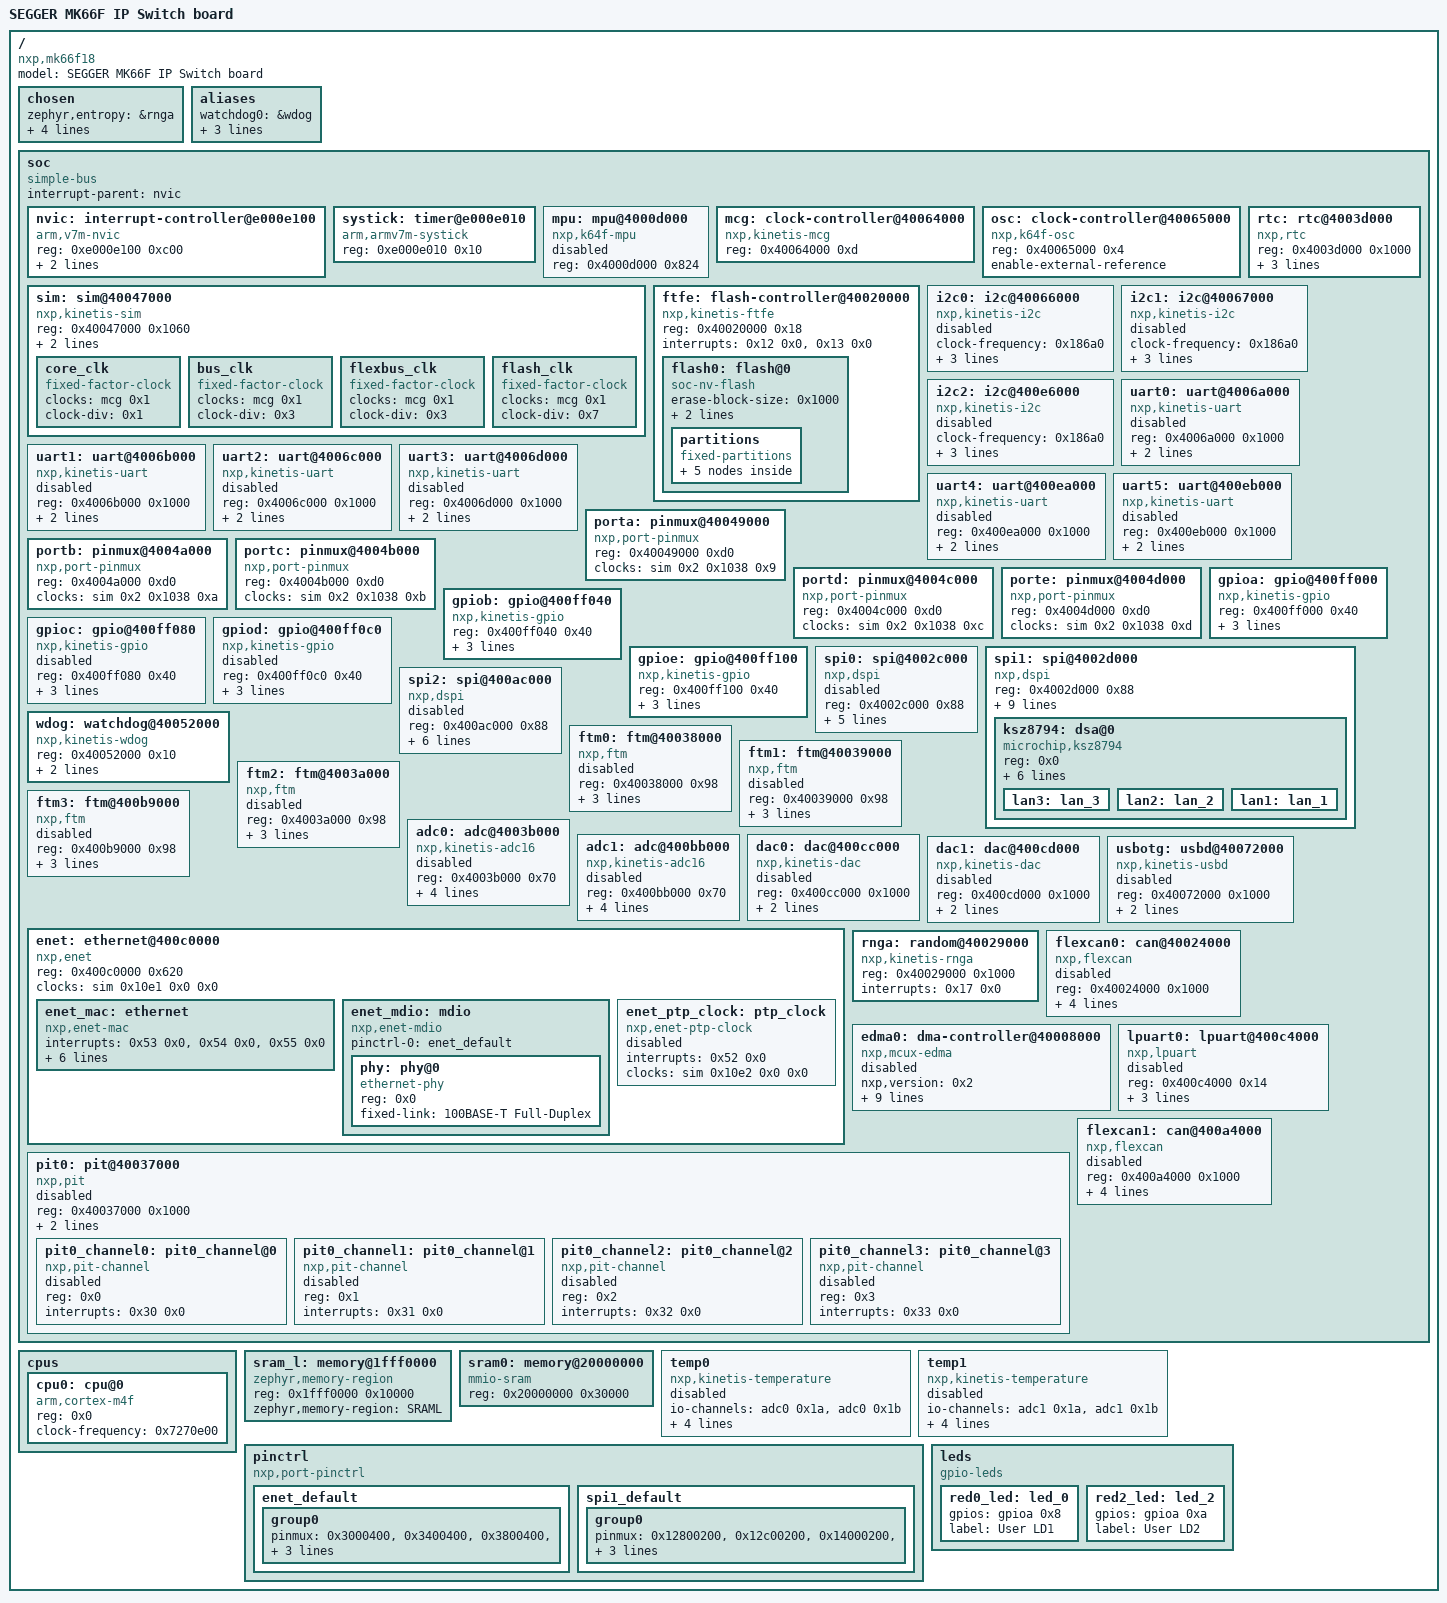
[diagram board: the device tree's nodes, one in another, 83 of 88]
/dts-v1/;

/* node '/' defined in zephyr/dts/common/skeleton.dtsi:9 */
/ {
	#address-cells = < 0x1 >;               /* in zephyr/dts/common/skeleton.dtsi:10 */
	#size-cells = < 0x1 >;                  /* in zephyr/dts/common/skeleton.dtsi:11 */
	model = "SEGGER MK66F IP Switch board"; /* in zephyr/boards/segger/ip_k66f/ip_k66f.dts:14 */
	compatible = "nxp,mk66f18",
	             "nxp,k66f",
	             "nxp,k6x";                 /* in zephyr/boards/segger/ip_k66f/ip_k66f.dts:15 */

	/* node '/chosen' defined in zephyr/dts/common/skeleton.dtsi:13 */
	chosen {
		zephyr,entropy = &rnga;                   /* in zephyr/dts/arm/nxp/nxp_k6x.dtsi:18 */
		zephyr,flash-controller = &ftfe;          /* in zephyr/dts/arm/nxp/nxp_k6x.dtsi:19 */
		zephyr,sram = &sram0;                     /* in zephyr/boards/segger/ip_k66f/ip_k66f.dts:24 */
		zephyr,flash = &flash0;                   /* in zephyr/boards/segger/ip_k66f/ip_k66f.dts:25 */
		zephyr,code-partition = &slot0_partition; /* in zephyr/boards/segger/ip_k66f/ip_k66f.dts:26 */
	};

	/* node '/aliases' defined in zephyr/dts/common/skeleton.dtsi:15 */
	aliases {
		watchdog0 = &wdog; /* in zephyr/dts/arm/nxp/nxp_k6x.dtsi:14 */
		led0 = &red0_led;  /* in zephyr/boards/segger/ip_k66f/ip_k66f.dts:18 */
		led2 = &red2_led;  /* in zephyr/boards/segger/ip_k66f/ip_k66f.dts:19 */
		dsa-spi = &spi1;   /* in zephyr/boards/segger/ip_k66f/ip_k66f.dts:20 */
	};

	/* node '/soc' defined in zephyr/dts/arm/armv7-m.dtsi:6 */
	soc {
		#address-cells = < 0x1 >;     /* in zephyr/dts/arm/armv7-m.dtsi:7 */
		#size-cells = < 0x1 >;        /* in zephyr/dts/arm/armv7-m.dtsi:8 */
		compatible = "simple-bus";    /* in zephyr/dts/arm/armv7-m.dtsi:9 */
		interrupt-parent = < &nvic >; /* in zephyr/dts/arm/armv7-m.dtsi:10 */
		ranges;                       /* in zephyr/dts/arm/armv7-m.dtsi:11 */

		/* node '/soc/interrupt-controller@e000e100' defined in zephyr/dts/arm/armv7-m.dtsi:13 */
		nvic: interrupt-controller@e000e100 {
			#address-cells = < 0x1 >;            /* in zephyr/dts/arm/armv7-m.dtsi:14 */
			compatible = "arm,v7m-nvic";         /* in zephyr/dts/arm/armv7-m.dtsi:15 */
			reg = < 0xe000e100 0xc00 >;          /* in zephyr/dts/arm/armv7-m.dtsi:16 */
			interrupt-controller;                /* in zephyr/dts/arm/armv7-m.dtsi:17 */
			#interrupt-cells = < 0x2 >;          /* in zephyr/dts/arm/armv7-m.dtsi:18 */
			arm,num-irq-priority-bits = < 0x4 >; /* in zephyr/dts/arm/nxp/nxp_k6x.dtsi:584 */
			phandle = < 0x1 >;                   /* in zephyr/dts/arm/armv7-m.dtsi:10 */
		};

		/* node '/soc/timer@e000e010' defined in zephyr/dts/arm/armv7-m.dtsi:21 */
		systick: timer@e000e010 {
			compatible = "arm,armv7m-systick"; /* in zephyr/dts/arm/armv7-m.dtsi:22 */
			reg = < 0xe000e010 0x10 >;         /* in zephyr/dts/arm/armv7-m.dtsi:23 */
		};

		/* node '/soc/mpu@4000d000' defined in zephyr/dts/arm/nxp/nxp_k6x.dtsi:82 */
		mpu: mpu@4000d000 {
			compatible = "nxp,k64f-mpu"; /* in zephyr/dts/arm/nxp/nxp_k6x.dtsi:83 */
			reg = < 0x4000d000 0x824 >;  /* in zephyr/dts/arm/nxp/nxp_k6x.dtsi:84 */
			status = "disabled";         /* in zephyr/dts/arm/nxp/nxp_k6x.dtsi:86 */
		};

		/* node '/soc/clock-controller@40064000' defined in zephyr/dts/arm/nxp/nxp_k6x.dtsi:89 */
		mcg: clock-controller@40064000 {
			compatible = "nxp,kinetis-mcg"; /* in zephyr/dts/arm/nxp/nxp_k6x.dtsi:90 */
			reg = < 0x40064000 0xd >;       /* in zephyr/dts/arm/nxp/nxp_k6x.dtsi:91 */
			#clock-cells = < 0x1 >;         /* in zephyr/dts/arm/nxp/nxp_k6x.dtsi:92 */
			phandle = < 0x2 >;              /* in zephyr/dts/arm/nxp/nxp_k6x.dtsi:118 */
		};

		/* node '/soc/clock-controller@40065000' defined in zephyr/dts/arm/nxp/nxp_k6x.dtsi:95 */
		osc: clock-controller@40065000 {
			compatible = "nxp,k64f-osc"; /* in zephyr/dts/arm/nxp/nxp_k6x.dtsi:96 */
			reg = < 0x40065000 0x4 >;    /* in zephyr/dts/arm/nxp/nxp_k6x.dtsi:97 */
			enable-external-reference;   /* in zephyr/dts/arm/nxp/nxp_k6x.dtsi:99 */
		};

		/* node '/soc/rtc@4003d000' defined in zephyr/dts/arm/nxp/nxp_k6x.dtsi:102 */
		rtc: rtc@4003d000 {
			compatible = "nxp,rtc";       /* in zephyr/dts/arm/nxp/nxp_k6x.dtsi:103 */
			reg = < 0x4003d000 0x1000 >;  /* in zephyr/dts/arm/nxp/nxp_k6x.dtsi:104 */
			interrupts = < 0x2e 0x0 >,
			             < 0x2f 0x0 >;    /* in zephyr/dts/arm/nxp/nxp_k6x.dtsi:105 */
			interrupt-names = "alarm",
			                  "seconds";  /* in zephyr/dts/arm/nxp/nxp_k6x.dtsi:106 */
			clock-frequency = < 0x8000 >; /* in zephyr/dts/arm/nxp/nxp_k6x.dtsi:107 */
			prescaler = < 0x8000 >;       /* in zephyr/dts/arm/nxp/nxp_k6x.dtsi:108 */
		};

		/* node '/soc/sim@40047000' defined in zephyr/dts/arm/nxp/nxp_k6x.dtsi:111 */
		sim: sim@40047000 {
			compatible = "nxp,kinetis-sim"; /* in zephyr/dts/arm/nxp/nxp_k6x.dtsi:112 */
			reg = < 0x40047000 0x1060 >;    /* in zephyr/dts/arm/nxp/nxp_k6x.dtsi:113 */
			#clock-cells = < 0x3 >;         /* in zephyr/dts/arm/nxp/nxp_k6x.dtsi:114 */
			pllfll-select = < 0x1 >;        /* in zephyr/boards/segger/ip_k66f/ip_k66f.dts:49 */
			er32k-select = < 0x2 >;         /* in zephyr/boards/segger/ip_k66f/ip_k66f.dts:50 */
			phandle = < 0x3 >;              /* in zephyr/dts/arm/nxp/nxp_k6x.dtsi:170 */

			/* node '/soc/sim@40047000/core_clk' defined in zephyr/dts/arm/nxp/nxp_k6x.dtsi:116 */
			core_clk {
				compatible = "fixed-factor-clock"; /* in zephyr/dts/arm/nxp/nxp_k6x.dtsi:117 */
				clocks = < &mcg 0x1 >;             /* in zephyr/dts/arm/nxp/nxp_k6x.dtsi:118 */
				clock-div = < 0x1 >;               /* in zephyr/dts/arm/nxp/nxp_k6x.dtsi:119 */
				#clock-cells = < 0x0 >;            /* in zephyr/dts/arm/nxp/nxp_k6x.dtsi:120 */
			};

			/* node '/soc/sim@40047000/bus_clk' defined in zephyr/dts/arm/nxp/nxp_k6x.dtsi:123 */
			bus_clk {
				compatible = "fixed-factor-clock"; /* in zephyr/dts/arm/nxp/nxp_k6x.dtsi:124 */
				clocks = < &mcg 0x1 >;             /* in zephyr/dts/arm/nxp/nxp_k6x.dtsi:125 */
				#clock-cells = < 0x0 >;            /* in zephyr/dts/arm/nxp/nxp_k6x.dtsi:127 */
				clock-div = < 0x3 >;               /* in zephyr/boards/segger/ip_k66f/ip_k66f.dts:53 */
			};

			/* node '/soc/sim@40047000/flexbus_clk' defined in zephyr/dts/arm/nxp/nxp_k6x.dtsi:130 */
			flexbus_clk {
				compatible = "fixed-factor-clock"; /* in zephyr/dts/arm/nxp/nxp_k6x.dtsi:131 */
				clocks = < &mcg 0x1 >;             /* in zephyr/dts/arm/nxp/nxp_k6x.dtsi:132 */
				clock-div = < 0x3 >;               /* in zephyr/dts/arm/nxp/nxp_k6x.dtsi:133 */
				#clock-cells = < 0x0 >;            /* in zephyr/dts/arm/nxp/nxp_k6x.dtsi:134 */
			};

			/* node '/soc/sim@40047000/flash_clk' defined in zephyr/dts/arm/nxp/nxp_k6x.dtsi:137 */
			flash_clk {
				compatible = "fixed-factor-clock"; /* in zephyr/dts/arm/nxp/nxp_k6x.dtsi:138 */
				clocks = < &mcg 0x1 >;             /* in zephyr/dts/arm/nxp/nxp_k6x.dtsi:139 */
				#clock-cells = < 0x0 >;            /* in zephyr/dts/arm/nxp/nxp_k6x.dtsi:141 */
				clock-div = < 0x7 >;               /* in zephyr/boards/segger/ip_k66f/ip_k66f.dts:57 */
			};
		};

		/* node '/soc/flash-controller@40020000' defined in zephyr/dts/arm/nxp/nxp_k6x.dtsi:145 */
		ftfe: flash-controller@40020000 {
			compatible = "nxp,kinetis-ftfe";      /* in zephyr/dts/arm/nxp/nxp_k6x.dtsi:146 */
			reg = < 0x40020000 0x18 >;            /* in zephyr/dts/arm/nxp/nxp_k6x.dtsi:147 */
			interrupts = < 0x12 0x0 >,
			             < 0x13 0x0 >;            /* in zephyr/dts/arm/nxp/nxp_k6x.dtsi:148 */
			interrupt-names = "command-complete",
			                  "read-collision";   /* in zephyr/dts/arm/nxp/nxp_k6x.dtsi:149 */
			status = "okay";                      /* in zephyr/dts/arm/nxp/nxp_k6x.dtsi:150 */
			#address-cells = < 0x1 >;             /* in zephyr/dts/arm/nxp/nxp_k6x.dtsi:152 */
			#size-cells = < 0x1 >;                /* in zephyr/dts/arm/nxp/nxp_k6x.dtsi:153 */

			/* node '/soc/flash-controller@40020000/flash@0' defined in zephyr/dts/arm/nxp/nxp_k6x.dtsi:155 */
			flash0: flash@0 {
				compatible = "soc-nv-flash";   /* in zephyr/dts/arm/nxp/nxp_k6x.dtsi:156 */
				erase-block-size = < 0x1000 >; /* in zephyr/dts/arm/nxp/nxp_k6x.dtsi:158 */
				write-block-size = < 0x8 >;    /* in zephyr/dts/arm/nxp/nxp_k6x.dtsi:159 */
				reg = < 0x0 0x200000 >;        /* in zephyr/dts/arm/nxp/nxp_k66.dtsi:12 */

				/* node '/soc/flash-controller@40020000/flash@0/partitions' defined in zephyr/boards/segger/ip_k66f/ip_k66f.dts:70 */
				partitions {
					compatible = "fixed-partitions"; /* in zephyr/boards/segger/ip_k66f/ip_k66f.dts:71 */
					#address-cells = < 0x1 >;        /* in zephyr/boards/segger/ip_k66f/ip_k66f.dts:72 */
					#size-cells = < 0x1 >;           /* in zephyr/boards/segger/ip_k66f/ip_k66f.dts:73 */

					/* node '/soc/flash-controller@40020000/flash@0/partitions/partition@0' defined in zephyr/boards/segger/ip_k66f/ip_k66f.dts:75 */
					boot_partition: partition@0 {
						label = "mcuboot";     /* in zephyr/boards/segger/ip_k66f/ip_k66f.dts:76 */
						reg = < 0x0 0x10000 >; /* in zephyr/boards/segger/ip_k66f/ip_k66f.dts:77 */
						read-only;             /* in zephyr/boards/segger/ip_k66f/ip_k66f.dts:78 */
					};

					/* node '/soc/flash-controller@40020000/flash@0/partitions/partition@1e000' defined in zephyr/boards/segger/ip_k66f/ip_k66f.dts:86 */
					storage_partition: partition@1e000 {
						label = "storage";        /* in zephyr/boards/segger/ip_k66f/ip_k66f.dts:87 */
						reg = < 0x1e000 0x2000 >; /* in zephyr/boards/segger/ip_k66f/ip_k66f.dts:88 */
					};

					/* node '/soc/flash-controller@40020000/flash@0/partitions/partition@20000' defined in zephyr/boards/segger/ip_k66f/ip_k66f.dts:91 */
					slot0_partition: partition@20000 {
						label = "image-0";         /* in zephyr/boards/segger/ip_k66f/ip_k66f.dts:92 */
						reg = < 0x20000 0x60000 >; /* in zephyr/boards/segger/ip_k66f/ip_k66f.dts:93 */
					};

					/* node '/soc/flash-controller@40020000/flash@0/partitions/partition@80000' defined in zephyr/boards/segger/ip_k66f/ip_k66f.dts:96 */
					slot1_partition: partition@80000 {
						label = "image-1";         /* in zephyr/boards/segger/ip_k66f/ip_k66f.dts:97 */
						reg = < 0x80000 0x60000 >; /* in zephyr/boards/segger/ip_k66f/ip_k66f.dts:98 */
					};

					/* node '/soc/flash-controller@40020000/flash@0/partitions/partition@e0000' defined in zephyr/boards/segger/ip_k66f/ip_k66f.dts:101 */
					scratch_partition: partition@e0000 {
						label = "image-scratch";   /* in zephyr/boards/segger/ip_k66f/ip_k66f.dts:102 */
						reg = < 0xe0000 0x20000 >; /* in zephyr/boards/segger/ip_k66f/ip_k66f.dts:103 */
					};
				};
			};
		};

		/* node '/soc/i2c@40066000' defined in zephyr/dts/arm/nxp/nxp_k6x.dtsi:163 */
		i2c0: i2c@40066000 {
			compatible = "nxp,kinetis-i2c";   /* in zephyr/dts/arm/nxp/nxp_k6x.dtsi:164 */
			clock-frequency = < 0x186a0 >;    /* in zephyr/dts/arm/nxp/nxp_k6x.dtsi:165 */
			#address-cells = < 0x1 >;         /* in zephyr/dts/arm/nxp/nxp_k6x.dtsi:166 */
			#size-cells = < 0x0 >;            /* in zephyr/dts/arm/nxp/nxp_k6x.dtsi:167 */
			reg = < 0x40066000 0x1000 >;      /* in zephyr/dts/arm/nxp/nxp_k6x.dtsi:168 */
			interrupts = < 0x18 0x0 >;        /* in zephyr/dts/arm/nxp/nxp_k6x.dtsi:169 */
			clocks = < &sim 0x2 0x1034 0x6 >; /* in zephyr/dts/arm/nxp/nxp_k6x.dtsi:170 */
			status = "disabled";              /* in zephyr/dts/arm/nxp/nxp_k6x.dtsi:171 */
		};

		/* node '/soc/i2c@40067000' defined in zephyr/dts/arm/nxp/nxp_k6x.dtsi:174 */
		i2c1: i2c@40067000 {
			compatible = "nxp,kinetis-i2c";   /* in zephyr/dts/arm/nxp/nxp_k6x.dtsi:175 */
			clock-frequency = < 0x186a0 >;    /* in zephyr/dts/arm/nxp/nxp_k6x.dtsi:176 */
			#address-cells = < 0x1 >;         /* in zephyr/dts/arm/nxp/nxp_k6x.dtsi:177 */
			#size-cells = < 0x0 >;            /* in zephyr/dts/arm/nxp/nxp_k6x.dtsi:178 */
			reg = < 0x40067000 0x1000 >;      /* in zephyr/dts/arm/nxp/nxp_k6x.dtsi:179 */
			interrupts = < 0x19 0x0 >;        /* in zephyr/dts/arm/nxp/nxp_k6x.dtsi:180 */
			clocks = < &sim 0x2 0x1034 0x7 >; /* in zephyr/dts/arm/nxp/nxp_k6x.dtsi:181 */
			status = "disabled";              /* in zephyr/dts/arm/nxp/nxp_k6x.dtsi:182 */
		};

		/* node '/soc/i2c@400e6000' defined in zephyr/dts/arm/nxp/nxp_k6x.dtsi:185 */
		i2c2: i2c@400e6000 {
			compatible = "nxp,kinetis-i2c";   /* in zephyr/dts/arm/nxp/nxp_k6x.dtsi:186 */
			clock-frequency = < 0x186a0 >;    /* in zephyr/dts/arm/nxp/nxp_k6x.dtsi:187 */
			#address-cells = < 0x1 >;         /* in zephyr/dts/arm/nxp/nxp_k6x.dtsi:188 */
			#size-cells = < 0x0 >;            /* in zephyr/dts/arm/nxp/nxp_k6x.dtsi:189 */
			reg = < 0x400e6000 0x1000 >;      /* in zephyr/dts/arm/nxp/nxp_k6x.dtsi:190 */
			interrupts = < 0x4a 0x0 >;        /* in zephyr/dts/arm/nxp/nxp_k6x.dtsi:191 */
			clocks = < &sim 0x2 0x1028 0x6 >; /* in zephyr/dts/arm/nxp/nxp_k6x.dtsi:192 */
			status = "disabled";              /* in zephyr/dts/arm/nxp/nxp_k6x.dtsi:193 */
		};

		/* node '/soc/uart@4006a000' defined in zephyr/dts/arm/nxp/nxp_k6x.dtsi:196 */
		uart0: uart@4006a000 {
			compatible = "nxp,kinetis-uart";  /* in zephyr/dts/arm/nxp/nxp_k6x.dtsi:197 */
			reg = < 0x4006a000 0x1000 >;      /* in zephyr/dts/arm/nxp/nxp_k6x.dtsi:198 */
			interrupts = < 0x1f 0x0 >,
			             < 0x20 0x0 >;        /* in zephyr/dts/arm/nxp/nxp_k6x.dtsi:199 */
			interrupt-names = "status",
			                  "error";        /* in zephyr/dts/arm/nxp/nxp_k6x.dtsi:200 */
			clocks = < &sim 0x0 0x1034 0xa >; /* in zephyr/dts/arm/nxp/nxp_k6x.dtsi:201 */
			status = "disabled";              /* in zephyr/dts/arm/nxp/nxp_k6x.dtsi:203 */
		};

		/* node '/soc/uart@4006b000' defined in zephyr/dts/arm/nxp/nxp_k6x.dtsi:206 */
		uart1: uart@4006b000 {
			compatible = "nxp,kinetis-uart";  /* in zephyr/dts/arm/nxp/nxp_k6x.dtsi:207 */
			reg = < 0x4006b000 0x1000 >;      /* in zephyr/dts/arm/nxp/nxp_k6x.dtsi:208 */
			interrupts = < 0x21 0x0 >,
			             < 0x22 0x0 >;        /* in zephyr/dts/arm/nxp/nxp_k6x.dtsi:209 */
			interrupt-names = "status",
			                  "error";        /* in zephyr/dts/arm/nxp/nxp_k6x.dtsi:210 */
			clocks = < &sim 0x0 0x1034 0xb >; /* in zephyr/dts/arm/nxp/nxp_k6x.dtsi:211 */
			status = "disabled";              /* in zephyr/dts/arm/nxp/nxp_k6x.dtsi:213 */
		};

		/* node '/soc/uart@4006c000' defined in zephyr/dts/arm/nxp/nxp_k6x.dtsi:216 */
		uart2: uart@4006c000 {
			compatible = "nxp,kinetis-uart";  /* in zephyr/dts/arm/nxp/nxp_k6x.dtsi:217 */
			reg = < 0x4006c000 0x1000 >;      /* in zephyr/dts/arm/nxp/nxp_k6x.dtsi:218 */
			interrupts = < 0x23 0x0 >,
			             < 0x24 0x0 >;        /* in zephyr/dts/arm/nxp/nxp_k6x.dtsi:219 */
			interrupt-names = "status",
			                  "error";        /* in zephyr/dts/arm/nxp/nxp_k6x.dtsi:220 */
			clocks = < &sim 0x2 0x1034 0xc >; /* in zephyr/dts/arm/nxp/nxp_k6x.dtsi:221 */
			status = "disabled";              /* in zephyr/dts/arm/nxp/nxp_k6x.dtsi:223 */
		};

		/* node '/soc/uart@4006d000' defined in zephyr/dts/arm/nxp/nxp_k6x.dtsi:226 */
		uart3: uart@4006d000 {
			compatible = "nxp,kinetis-uart";  /* in zephyr/dts/arm/nxp/nxp_k6x.dtsi:227 */
			reg = < 0x4006d000 0x1000 >;      /* in zephyr/dts/arm/nxp/nxp_k6x.dtsi:228 */
			interrupts = < 0x25 0x0 >,
			             < 0x26 0x0 >;        /* in zephyr/dts/arm/nxp/nxp_k6x.dtsi:229 */
			interrupt-names = "status",
			                  "error";        /* in zephyr/dts/arm/nxp/nxp_k6x.dtsi:230 */
			clocks = < &sim 0x2 0x1034 0xd >; /* in zephyr/dts/arm/nxp/nxp_k6x.dtsi:231 */
			status = "disabled";              /* in zephyr/dts/arm/nxp/nxp_k6x.dtsi:233 */
		};

		/* node '/soc/uart@400ea000' defined in zephyr/dts/arm/nxp/nxp_k6x.dtsi:236 */
		uart4: uart@400ea000 {
			compatible = "nxp,kinetis-uart";  /* in zephyr/dts/arm/nxp/nxp_k6x.dtsi:237 */
			reg = < 0x400ea000 0x1000 >;      /* in zephyr/dts/arm/nxp/nxp_k6x.dtsi:238 */
			interrupts = < 0x42 0x0 >,
			             < 0x43 0x0 >;        /* in zephyr/dts/arm/nxp/nxp_k6x.dtsi:239 */
			interrupt-names = "status",
			                  "error";        /* in zephyr/dts/arm/nxp/nxp_k6x.dtsi:240 */
			clocks = < &sim 0x2 0x1028 0xa >; /* in zephyr/dts/arm/nxp/nxp_k6x.dtsi:241 */
			status = "disabled";              /* in zephyr/dts/arm/nxp/nxp_k6x.dtsi:243 */
		};

		/* node '/soc/uart@400eb000' defined in zephyr/dts/arm/nxp/nxp_k6x.dtsi:246 */
		uart5: uart@400eb000 {
			compatible = "nxp,kinetis-uart";  /* in zephyr/dts/arm/nxp/nxp_k6x.dtsi:247 */
			reg = < 0x400eb000 0x1000 >;      /* in zephyr/dts/arm/nxp/nxp_k6x.dtsi:248 */
			interrupts = < 0x44 0x0 >,
			             < 0x45 0x0 >;        /* in zephyr/dts/arm/nxp/nxp_k6x.dtsi:249 */
			interrupt-names = "status",
			                  "error";        /* in zephyr/dts/arm/nxp/nxp_k6x.dtsi:250 */
			clocks = < &sim 0x2 0x1028 0xb >; /* in zephyr/dts/arm/nxp/nxp_k6x.dtsi:251 */
			status = "disabled";              /* in zephyr/dts/arm/nxp/nxp_k6x.dtsi:253 */
		};

		/* node '/soc/pinmux@40049000' defined in zephyr/dts/arm/nxp/nxp_k6x.dtsi:256 */
		porta: pinmux@40049000 {
			compatible = "nxp,port-pinmux";   /* in zephyr/dts/arm/nxp/nxp_k6x.dtsi:257 */
			reg = < 0x40049000 0xd0 >;        /* in zephyr/dts/arm/nxp/nxp_k6x.dtsi:258 */
			clocks = < &sim 0x2 0x1038 0x9 >; /* in zephyr/dts/arm/nxp/nxp_k6x.dtsi:259 */
			phandle = < 0x4 >;                /* in zephyr/dts/arm/nxp/nxp_k6x.dtsi:293 */
		};

		/* node '/soc/pinmux@4004a000' defined in zephyr/dts/arm/nxp/nxp_k6x.dtsi:262 */
		portb: pinmux@4004a000 {
			compatible = "nxp,port-pinmux";   /* in zephyr/dts/arm/nxp/nxp_k6x.dtsi:263 */
			reg = < 0x4004a000 0xd0 >;        /* in zephyr/dts/arm/nxp/nxp_k6x.dtsi:264 */
			clocks = < &sim 0x2 0x1038 0xa >; /* in zephyr/dts/arm/nxp/nxp_k6x.dtsi:265 */
			phandle = < 0x5 >;                /* in zephyr/dts/arm/nxp/nxp_k6x.dtsi:303 */
		};

		/* node '/soc/pinmux@4004b000' defined in zephyr/dts/arm/nxp/nxp_k6x.dtsi:268 */
		portc: pinmux@4004b000 {
			compatible = "nxp,port-pinmux";   /* in zephyr/dts/arm/nxp/nxp_k6x.dtsi:269 */
			reg = < 0x4004b000 0xd0 >;        /* in zephyr/dts/arm/nxp/nxp_k6x.dtsi:270 */
			clocks = < &sim 0x2 0x1038 0xb >; /* in zephyr/dts/arm/nxp/nxp_k6x.dtsi:271 */
			phandle = < 0x6 >;                /* in zephyr/dts/arm/nxp/nxp_k6x.dtsi:313 */
		};

		/* node '/soc/pinmux@4004c000' defined in zephyr/dts/arm/nxp/nxp_k6x.dtsi:274 */
		portd: pinmux@4004c000 {
			compatible = "nxp,port-pinmux";   /* in zephyr/dts/arm/nxp/nxp_k6x.dtsi:275 */
			reg = < 0x4004c000 0xd0 >;        /* in zephyr/dts/arm/nxp/nxp_k6x.dtsi:276 */
			clocks = < &sim 0x2 0x1038 0xc >; /* in zephyr/dts/arm/nxp/nxp_k6x.dtsi:277 */
			phandle = < 0x7 >;                /* in zephyr/dts/arm/nxp/nxp_k6x.dtsi:323 */
		};

		/* node '/soc/pinmux@4004d000' defined in zephyr/dts/arm/nxp/nxp_k6x.dtsi:280 */
		porte: pinmux@4004d000 {
			compatible = "nxp,port-pinmux";   /* in zephyr/dts/arm/nxp/nxp_k6x.dtsi:281 */
			reg = < 0x4004d000 0xd0 >;        /* in zephyr/dts/arm/nxp/nxp_k6x.dtsi:282 */
			clocks = < &sim 0x2 0x1038 0xd >; /* in zephyr/dts/arm/nxp/nxp_k6x.dtsi:283 */
			phandle = < 0x8 >;                /* in zephyr/dts/arm/nxp/nxp_k6x.dtsi:333 */
		};

		/* node '/soc/gpio@400ff000' defined in zephyr/dts/arm/nxp/nxp_k6x.dtsi:286 */
		gpioa: gpio@400ff000 {
			compatible = "nxp,kinetis-gpio"; /* in zephyr/dts/arm/nxp/nxp_k6x.dtsi:287 */
			reg = < 0x400ff000 0x40 >;       /* in zephyr/dts/arm/nxp/nxp_k6x.dtsi:289 */
			interrupts = < 0x3b 0x2 >;       /* in zephyr/dts/arm/nxp/nxp_k6x.dtsi:290 */
			gpio-controller;                 /* in zephyr/dts/arm/nxp/nxp_k6x.dtsi:291 */
			#gpio-cells = < 0x2 >;           /* in zephyr/dts/arm/nxp/nxp_k6x.dtsi:292 */
			nxp,kinetis-port = < &porta >;   /* in zephyr/dts/arm/nxp/nxp_k6x.dtsi:293 */
			status = "okay";                 /* in zephyr/boards/segger/ip_k66f/ip_k66f.dts:159 */
			phandle = < 0x14 >;              /* in zephyr/boards/segger/ip_k66f/ip_k66f.dts:33 */
		};

		/* node '/soc/gpio@400ff040' defined in zephyr/dts/arm/nxp/nxp_k6x.dtsi:296 */
		gpiob: gpio@400ff040 {
			compatible = "nxp,kinetis-gpio"; /* in zephyr/dts/arm/nxp/nxp_k6x.dtsi:297 */
			reg = < 0x400ff040 0x40 >;       /* in zephyr/dts/arm/nxp/nxp_k6x.dtsi:299 */
			interrupts = < 0x3c 0x2 >;       /* in zephyr/dts/arm/nxp/nxp_k6x.dtsi:300 */
			gpio-controller;                 /* in zephyr/dts/arm/nxp/nxp_k6x.dtsi:301 */
			#gpio-cells = < 0x2 >;           /* in zephyr/dts/arm/nxp/nxp_k6x.dtsi:302 */
			nxp,kinetis-port = < &portb >;   /* in zephyr/dts/arm/nxp/nxp_k6x.dtsi:303 */
			status = "okay";                 /* in zephyr/boards/segger/ip_k66f/ip_k66f.dts:163 */
			phandle = < 0xc >;               /* in zephyr/boards/segger/ip_k66f/ip_k66f.dts:143 */
		};

		/* node '/soc/gpio@400ff080' defined in zephyr/dts/arm/nxp/nxp_k6x.dtsi:306 */
		gpioc: gpio@400ff080 {
			compatible = "nxp,kinetis-gpio"; /* in zephyr/dts/arm/nxp/nxp_k6x.dtsi:307 */
			status = "disabled";             /* in zephyr/dts/arm/nxp/nxp_k6x.dtsi:308 */
			reg = < 0x400ff080 0x40 >;       /* in zephyr/dts/arm/nxp/nxp_k6x.dtsi:309 */
			interrupts = < 0x3d 0x2 >;       /* in zephyr/dts/arm/nxp/nxp_k6x.dtsi:310 */
			gpio-controller;                 /* in zephyr/dts/arm/nxp/nxp_k6x.dtsi:311 */
			#gpio-cells = < 0x2 >;           /* in zephyr/dts/arm/nxp/nxp_k6x.dtsi:312 */
			nxp,kinetis-port = < &portc >;   /* in zephyr/dts/arm/nxp/nxp_k6x.dtsi:313 */
		};

		/* node '/soc/gpio@400ff0c0' defined in zephyr/dts/arm/nxp/nxp_k6x.dtsi:316 */
		gpiod: gpio@400ff0c0 {
			compatible = "nxp,kinetis-gpio"; /* in zephyr/dts/arm/nxp/nxp_k6x.dtsi:317 */
			status = "disabled";             /* in zephyr/dts/arm/nxp/nxp_k6x.dtsi:318 */
			reg = < 0x400ff0c0 0x40 >;       /* in zephyr/dts/arm/nxp/nxp_k6x.dtsi:319 */
			interrupts = < 0x3e 0x2 >;       /* in zephyr/dts/arm/nxp/nxp_k6x.dtsi:320 */
			gpio-controller;                 /* in zephyr/dts/arm/nxp/nxp_k6x.dtsi:321 */
			#gpio-cells = < 0x2 >;           /* in zephyr/dts/arm/nxp/nxp_k6x.dtsi:322 */
			nxp,kinetis-port = < &portd >;   /* in zephyr/dts/arm/nxp/nxp_k6x.dtsi:323 */
		};

		/* node '/soc/gpio@400ff100' defined in zephyr/dts/arm/nxp/nxp_k6x.dtsi:326 */
		gpioe: gpio@400ff100 {
			compatible = "nxp,kinetis-gpio"; /* in zephyr/dts/arm/nxp/nxp_k6x.dtsi:327 */
			reg = < 0x400ff100 0x40 >;       /* in zephyr/dts/arm/nxp/nxp_k6x.dtsi:329 */
			interrupts = < 0x3f 0x2 >;       /* in zephyr/dts/arm/nxp/nxp_k6x.dtsi:330 */
			gpio-controller;                 /* in zephyr/dts/arm/nxp/nxp_k6x.dtsi:331 */
			#gpio-cells = < 0x2 >;           /* in zephyr/dts/arm/nxp/nxp_k6x.dtsi:332 */
			nxp,kinetis-port = < &porte >;   /* in zephyr/dts/arm/nxp/nxp_k6x.dtsi:333 */
			status = "okay";                 /* in zephyr/boards/segger/ip_k66f/ip_k66f.dts:167 */
			phandle = < 0xb >;               /* in zephyr/boards/segger/ip_k66f/ip_k66f.dts:136 */
		};

		/* node '/soc/spi@4002c000' defined in zephyr/dts/arm/nxp/nxp_k6x.dtsi:336 */
		spi0: spi@4002c000 {
			compatible = "nxp,dspi";          /* in zephyr/dts/arm/nxp/nxp_k6x.dtsi:337 */
			reg = < 0x4002c000 0x88 >;        /* in zephyr/dts/arm/nxp/nxp_k6x.dtsi:338 */
			interrupts = < 0x1a 0x3 >;        /* in zephyr/dts/arm/nxp/nxp_k6x.dtsi:339 */
			dmas = < &edma0 0x0 0xe >,
			       < &edma0 0x0 0xf >;        /* in zephyr/dts/arm/nxp/nxp_k6x.dtsi:340 */
			dma-names = "rx",
			            "tx";                 /* in zephyr/dts/arm/nxp/nxp_k6x.dtsi:341 */
			rx-fifo-size = < 0x4 >;           /* in zephyr/dts/arm/nxp/nxp_k6x.dtsi:342 */
			tx-fifo-size = < 0x4 >;           /* in zephyr/dts/arm/nxp/nxp_k6x.dtsi:343 */
			clocks = < &sim 0x2 0x103c 0xc >; /* in zephyr/dts/arm/nxp/nxp_k6x.dtsi:344 */
			#address-cells = < 0x1 >;         /* in zephyr/dts/arm/nxp/nxp_k6x.dtsi:345 */
			#size-cells = < 0x0 >;            /* in zephyr/dts/arm/nxp/nxp_k6x.dtsi:346 */
			status = "disabled";              /* in zephyr/dts/arm/nxp/nxp_k6x.dtsi:347 */
		};

		/* node '/soc/spi@4002d000' defined in zephyr/dts/arm/nxp/nxp_k6x.dtsi:350 */
		spi1: spi@4002d000 {
			compatible = "nxp,dspi";          /* in zephyr/dts/arm/nxp/nxp_k6x.dtsi:351 */
			reg = < 0x4002d000 0x88 >;        /* in zephyr/dts/arm/nxp/nxp_k6x.dtsi:352 */
			interrupts = < 0x1b 0x3 >;        /* in zephyr/dts/arm/nxp/nxp_k6x.dtsi:353 */
			dmas = < &edma0 0x0 0x10 >,
			       < &edma0 0x0 0x10 >;       /* in zephyr/dts/arm/nxp/nxp_k6x.dtsi:354 */
			dma-names = "rx",
			            "tx";                 /* in zephyr/dts/arm/nxp/nxp_k6x.dtsi:355 */
			rx-fifo-size = < 0x1 >;           /* in zephyr/dts/arm/nxp/nxp_k6x.dtsi:356 */
			tx-fifo-size = < 0x1 >;           /* in zephyr/dts/arm/nxp/nxp_k6x.dtsi:357 */
			nxp,rx-tx-chn-share;              /* in zephyr/dts/arm/nxp/nxp_k6x.dtsi:358 */
			clocks = < &sim 0x2 0x103c 0xd >; /* in zephyr/dts/arm/nxp/nxp_k6x.dtsi:359 */
			#address-cells = < 0x1 >;         /* in zephyr/dts/arm/nxp/nxp_k6x.dtsi:360 */
			#size-cells = < 0x0 >;            /* in zephyr/dts/arm/nxp/nxp_k6x.dtsi:361 */
			status = "okay";                  /* in zephyr/boards/segger/ip_k66f/ip_k66f.dts:131 */
			pinctrl-0 = < &spi1_default >;    /* in zephyr/boards/segger/ip_k66f/ip_k66f.dts:132 */
			pinctrl-names = "default";        /* in zephyr/boards/segger/ip_k66f/ip_k66f.dts:133 */
			clock-frequency = < 0x29f6300 >;  /* in zephyr/boards/segger/ip_k66f/ip_k66f.dts:135 */
			cs-gpios = < &gpioe 0x4 0x1 >;    /* in zephyr/boards/segger/ip_k66f/ip_k66f.dts:136 */

			/* node '/soc/spi@4002d000/dsa@0' defined in zephyr/boards/segger/ip_k66f/ip_k66f.dts:138 */
			ksz8794: dsa@0 {
				compatible = "microchip,ksz8794";  /* in zephyr/boards/segger/ip_k66f/ip_k66f.dts:139 */
				reg = < 0x0 >;                     /* in zephyr/boards/segger/ip_k66f/ip_k66f.dts:140 */
				spi-max-frequency = < 0x29f6300 >; /* in zephyr/boards/segger/ip_k66f/ip_k66f.dts:142 */
				reset-gpios = < &gpiob 0x16 0x1 >; /* in zephyr/boards/segger/ip_k66f/ip_k66f.dts:143 */
				spi-cpol;                          /* in zephyr/boards/segger/ip_k66f/ip_k66f.dts:145 */
				spi-cpha;                          /* in zephyr/boards/segger/ip_k66f/ip_k66f.dts:146 */
				dsa-master-port = < &enet_mac >;   /* in zephyr/boards/segger/ip_k66f/ip_k66f.dts:147 */
				dsa-slave-ports = < 0x3 >;         /* in zephyr/boards/segger/ip_k66f/ip_k66f.dts:148 */

				/* node '/soc/spi@4002d000/dsa@0/lan_3' defined in zephyr/boards/segger/ip_k66f/ip_k66f.dts:150 */
				lan3: lan_3 {
				};

				/* node '/soc/spi@4002d000/dsa@0/lan_2' defined in zephyr/boards/segger/ip_k66f/ip_k66f.dts:152 */
				lan2: lan_2 {
				};

				/* node '/soc/spi@4002d000/dsa@0/lan_1' defined in zephyr/boards/segger/ip_k66f/ip_k66f.dts:154 */
				lan1: lan_1 {
				};
			};
		};

		/* node '/soc/spi@400ac000' defined in zephyr/dts/arm/nxp/nxp_k6x.dtsi:365 */
		spi2: spi@400ac000 {
			compatible = "nxp,dspi";          /* in zephyr/dts/arm/nxp/nxp_k6x.dtsi:366 */
			reg = < 0x400ac000 0x88 >;        /* in zephyr/dts/arm/nxp/nxp_k6x.dtsi:367 */
			interrupts = < 0x41 0x3 >;        /* in zephyr/dts/arm/nxp/nxp_k6x.dtsi:368 */
			dmas = < &edma0 0x0 0x26 >,
			       < &edma0 0x0 0x27 >;       /* in zephyr/dts/arm/nxp/nxp_k6x.dtsi:369 */
			dma-names = "rx",
			            "tx";                 /* in zephyr/dts/arm/nxp/nxp_k6x.dtsi:370 */
			rx-fifo-size = < 0x1 >;           /* in zephyr/dts/arm/nxp/nxp_k6x.dtsi:371 */
			tx-fifo-size = < 0x1 >;           /* in zephyr/dts/arm/nxp/nxp_k6x.dtsi:372 */
			nxp,rx-tx-chn-share;              /* in zephyr/dts/arm/nxp/nxp_k6x.dtsi:373 */
			clocks = < &sim 0x2 0x1030 0xc >; /* in zephyr/dts/arm/nxp/nxp_k6x.dtsi:374 */
			#address-cells = < 0x1 >;         /* in zephyr/dts/arm/nxp/nxp_k6x.dtsi:375 */
			#size-cells = < 0x0 >;            /* in zephyr/dts/arm/nxp/nxp_k6x.dtsi:376 */
			status = "disabled";              /* in zephyr/dts/arm/nxp/nxp_k6x.dtsi:377 */
		};

		/* node '/soc/watchdog@40052000' defined in zephyr/dts/arm/nxp/nxp_k6x.dtsi:380 */
		wdog: watchdog@40052000 {
			compatible = "nxp,kinetis-wdog"; /* in zephyr/dts/arm/nxp/nxp_k6x.dtsi:381 */
			reg = < 0x40052000 0x10 >;       /* in zephyr/dts/arm/nxp/nxp_k6x.dtsi:382 */
			interrupts = < 0x16 0x0 >;       /* in zephyr/dts/arm/nxp/nxp_k6x.dtsi:383 */
			clocks = < &sim 0x13 0x0 0x0 >;  /* in zephyr/dts/arm/nxp/nxp_k6x.dtsi:384 */
		};

		/* node '/soc/ftm@40038000' defined in zephyr/dts/arm/nxp/nxp_k6x.dtsi:387 */
		ftm0: ftm@40038000 {
			compatible = "nxp,ftm";    /* in zephyr/dts/arm/nxp/nxp_k6x.dtsi:388 */
			reg = < 0x40038000 0x98 >; /* in zephyr/dts/arm/nxp/nxp_k6x.dtsi:389 */
			interrupts = < 0x2a 0x0 >; /* in zephyr/dts/arm/nxp/nxp_k6x.dtsi:390 */
			clocks = < &mcg 0x0 >;     /* in zephyr/dts/arm/nxp/nxp_k6x.dtsi:391 */
			prescaler = < 0x10 >;      /* in zephyr/dts/arm/nxp/nxp_k6x.dtsi:392 */
			status = "disabled";       /* in zephyr/dts/arm/nxp/nxp_k6x.dtsi:393 */
		};

		/* node '/soc/ftm@40039000' defined in zephyr/dts/arm/nxp/nxp_k6x.dtsi:396 */
		ftm1: ftm@40039000 {
			compatible = "nxp,ftm";    /* in zephyr/dts/arm/nxp/nxp_k6x.dtsi:397 */
			reg = < 0x40039000 0x98 >; /* in zephyr/dts/arm/nxp/nxp_k6x.dtsi:398 */
			interrupts = < 0x2b 0x0 >; /* in zephyr/dts/arm/nxp/nxp_k6x.dtsi:399 */
			clocks = < &mcg 0x0 >;     /* in zephyr/dts/arm/nxp/nxp_k6x.dtsi:400 */
			prescaler = < 0x10 >;      /* in zephyr/dts/arm/nxp/nxp_k6x.dtsi:401 */
			status = "disabled";       /* in zephyr/dts/arm/nxp/nxp_k6x.dtsi:402 */
		};

		/* node '/soc/ftm@4003a000' defined in zephyr/dts/arm/nxp/nxp_k6x.dtsi:405 */
		ftm2: ftm@4003a000 {
			compatible = "nxp,ftm";    /* in zephyr/dts/arm/nxp/nxp_k6x.dtsi:406 */
			reg = < 0x4003a000 0x98 >; /* in zephyr/dts/arm/nxp/nxp_k6x.dtsi:407 */
			interrupts = < 0x2c 0x0 >; /* in zephyr/dts/arm/nxp/nxp_k6x.dtsi:408 */
			clocks = < &mcg 0x0 >;     /* in zephyr/dts/arm/nxp/nxp_k6x.dtsi:409 */
			prescaler = < 0x10 >;      /* in zephyr/dts/arm/nxp/nxp_k6x.dtsi:410 */
			status = "disabled";       /* in zephyr/dts/arm/nxp/nxp_k6x.dtsi:411 */
		};

		/* node '/soc/ftm@400b9000' defined in zephyr/dts/arm/nxp/nxp_k6x.dtsi:414 */
		ftm3: ftm@400b9000 {
			compatible = "nxp,ftm";    /* in zephyr/dts/arm/nxp/nxp_k6x.dtsi:415 */
			reg = < 0x400b9000 0x98 >; /* in zephyr/dts/arm/nxp/nxp_k6x.dtsi:416 */
			interrupts = < 0x47 0x0 >; /* in zephyr/dts/arm/nxp/nxp_k6x.dtsi:417 */
			clocks = < &mcg 0x0 >;     /* in zephyr/dts/arm/nxp/nxp_k6x.dtsi:418 */
			prescaler = < 0x10 >;      /* in zephyr/dts/arm/nxp/nxp_k6x.dtsi:419 */
			status = "disabled";       /* in zephyr/dts/arm/nxp/nxp_k6x.dtsi:420 */
		};

		/* node '/soc/adc@4003b000' defined in zephyr/dts/arm/nxp/nxp_k6x.dtsi:423 */
		adc0: adc@4003b000 {
			compatible = "nxp,kinetis-adc16"; /* in zephyr/dts/arm/nxp/nxp_k6x.dtsi:424 */
			reg = < 0x4003b000 0x70 >;        /* in zephyr/dts/arm/nxp/nxp_k6x.dtsi:425 */
			clocks = < &sim 0x7 0x0 0xf >,
			         < &sim 0x7 0x7 0x80 >;   /* in zephyr/dts/arm/nxp/nxp_k6x.dtsi:426 */
			dmas = < &edma0 0x0 0x28 >;       /* in zephyr/dts/arm/nxp/nxp_k6x.dtsi:428 */
			dma-names = "adc0";               /* in zephyr/dts/arm/nxp/nxp_k6x.dtsi:429 */
			clk-source = < 0x0 >;             /* in zephyr/dts/arm/nxp/nxp_k6x.dtsi:430 */
			interrupts = < 0x27 0x0 >;        /* in zephyr/dts/arm/nxp/nxp_k6x.dtsi:431 */
			status = "disabled";              /* in zephyr/dts/arm/nxp/nxp_k6x.dtsi:432 */
			#io-channel-cells = < 0x1 >;      /* in zephyr/dts/arm/nxp/nxp_k6x.dtsi:433 */
			phandle = < 0x12 >;               /* in zephyr/dts/arm/nxp/nxp_k6x.dtsi:55 */
		};

		/* node '/soc/adc@400bb000' defined in zephyr/dts/arm/nxp/nxp_k6x.dtsi:436 */
		adc1: adc@400bb000 {
			compatible = "nxp,kinetis-adc16"; /* in zephyr/dts/arm/nxp/nxp_k6x.dtsi:437 */
			reg = < 0x400bb000 0x70 >;        /* in zephyr/dts/arm/nxp/nxp_k6x.dtsi:438 */
			clocks = < &sim 0x7 0x8 0xf00 >,
			         < &sim 0x7 0xf 0x8000 >; /* in zephyr/dts/arm/nxp/nxp_k6x.dtsi:439 */
			dmas = < &edma0 0x0 0x29 >;       /* in zephyr/dts/arm/nxp/nxp_k6x.dtsi:441 */
			dma-names = "adc1";               /* in zephyr/dts/arm/nxp/nxp_k6x.dtsi:442 */
			clk-source = < 0x0 >;             /* in zephyr/dts/arm/nxp/nxp_k6x.dtsi:443 */
			interrupts = < 0x49 0x0 >;        /* in zephyr/dts/arm/nxp/nxp_k6x.dtsi:444 */
			status = "disabled";              /* in zephyr/dts/arm/nxp/nxp_k6x.dtsi:445 */
			#io-channel-cells = < 0x1 >;      /* in zephyr/dts/arm/nxp/nxp_k6x.dtsi:446 */
			phandle = < 0x13 >;               /* in zephyr/dts/arm/nxp/nxp_k6x.dtsi:66 */
		};

		/* node '/soc/dac@400cc000' defined in zephyr/dts/arm/nxp/nxp_k6x.dtsi:449 */
		dac0: dac@400cc000 {
			compatible = "nxp,kinetis-dac"; /* in zephyr/dts/arm/nxp/nxp_k6x.dtsi:450 */
			reg = < 0x400cc000 0x1000 >;    /* in zephyr/dts/arm/nxp/nxp_k6x.dtsi:451 */
			interrupts = < 0x38 0x0 >;      /* in zephyr/dts/arm/nxp/nxp_k6x.dtsi:452 */
			voltage-reference = < 0x1 >;    /* in zephyr/dts/arm/nxp/nxp_k6x.dtsi:453 */
			status = "disabled";            /* in zephyr/dts/arm/nxp/nxp_k6x.dtsi:454 */
			#io-channel-cells = < 0x1 >;    /* in zephyr/dts/arm/nxp/nxp_k6x.dtsi:455 */
		};

		/* node '/soc/dac@400cd000' defined in zephyr/dts/arm/nxp/nxp_k6x.dtsi:458 */
		dac1: dac@400cd000 {
			compatible = "nxp,kinetis-dac"; /* in zephyr/dts/arm/nxp/nxp_k6x.dtsi:459 */
			reg = < 0x400cd000 0x1000 >;    /* in zephyr/dts/arm/nxp/nxp_k6x.dtsi:460 */
			interrupts = < 0x48 0x0 >;      /* in zephyr/dts/arm/nxp/nxp_k6x.dtsi:461 */
			voltage-reference = < 0x1 >;    /* in zephyr/dts/arm/nxp/nxp_k6x.dtsi:462 */
			status = "disabled";            /* in zephyr/dts/arm/nxp/nxp_k6x.dtsi:463 */
			#io-channel-cells = < 0x1 >;    /* in zephyr/dts/arm/nxp/nxp_k6x.dtsi:464 */
		};

		/* node '/soc/usbd@40072000' defined in zephyr/dts/arm/nxp/nxp_k6x.dtsi:467 */
		usbotg: usbd@40072000 {
			compatible = "nxp,kinetis-usbd"; /* in zephyr/dts/arm/nxp/nxp_k6x.dtsi:468 */
			reg = < 0x40072000 0x1000 >;     /* in zephyr/dts/arm/nxp/nxp_k6x.dtsi:469 */
			interrupts = < 0x35 0x1 >;       /* in zephyr/dts/arm/nxp/nxp_k6x.dtsi:470 */
			interrupt-names = "usb_otg";     /* in zephyr/dts/arm/nxp/nxp_k6x.dtsi:471 */
			num-bidir-endpoints = < 0x10 >;  /* in zephyr/dts/arm/nxp/nxp_k6x.dtsi:472 */
			status = "disabled";             /* in zephyr/dts/arm/nxp/nxp_k6x.dtsi:473 */
		};

		/* node '/soc/ethernet@400c0000' defined in zephyr/dts/arm/nxp/nxp_k6x.dtsi:476 */
		enet: ethernet@400c0000 {
			compatible = "nxp,enet";          /* in zephyr/dts/arm/nxp/nxp_k6x.dtsi:477 */
			reg = < 0x400c0000 0x620 >;       /* in zephyr/dts/arm/nxp/nxp_k6x.dtsi:478 */
			clocks = < &sim 0x10e1 0x0 0x0 >; /* in zephyr/dts/arm/nxp/nxp_k6x.dtsi:479 */

			/* node '/soc/ethernet@400c0000/ethernet' defined in zephyr/dts/arm/nxp/nxp_k6x.dtsi:481 */
			enet_mac: ethernet {
				compatible = "nxp,enet-mac";     /* in zephyr/dts/arm/nxp/nxp_k6x.dtsi:482 */
				interrupts = < 0x53 0x0 >,
				             < 0x54 0x0 >,
				             < 0x55 0x0 >;       /* in zephyr/dts/arm/nxp/nxp_k6x.dtsi:483 */
				interrupt-names = "TX",
				                  "RX",
				                  "ERR";         /* in zephyr/dts/arm/nxp/nxp_k6x.dtsi:484 */
				nxp,mdio = < &enet_mdio >;       /* in zephyr/dts/arm/nxp/nxp_k6x.dtsi:485 */
				ptp-clock = < &enet_ptp_clock >; /* in zephyr/dts/arm/nxp/nxp_k6x.dtsi:486 */
				status = "okay";                 /* in zephyr/boards/segger/ip_k66f/ip_k66f.dts:109 */
				pinctrl-0 = < &enet_default >;   /* in zephyr/boards/segger/ip_k66f/ip_k66f.dts:110 */
				pinctrl-names = "default";       /* in zephyr/boards/segger/ip_k66f/ip_k66f.dts:111 */
				zephyr,random-mac-address;       /* in zephyr/boards/segger/ip_k66f/ip_k66f.dts:112 */
				phy-connection-type = "rmii";    /* in zephyr/boards/segger/ip_k66f/ip_k66f.dts:113 */
				phy-handle = < &phy >;           /* in zephyr/boards/segger/ip_k66f/ip_k66f.dts:114 */
				phandle = < 0xd >;               /* in zephyr/boards/segger/ip_k66f/ip_k66f.dts:147 */
			};

			/* node '/soc/ethernet@400c0000/mdio' defined in zephyr/dts/arm/nxp/nxp_k6x.dtsi:491 */
			enet_mdio: mdio {
				compatible = "nxp,enet-mdio";  /* in zephyr/dts/arm/nxp/nxp_k6x.dtsi:492 */
				#address-cells = < 0x1 >;      /* in zephyr/dts/arm/nxp/nxp_k6x.dtsi:494 */
				#size-cells = < 0x0 >;         /* in zephyr/dts/arm/nxp/nxp_k6x.dtsi:495 */
				status = "okay";               /* in zephyr/boards/segger/ip_k66f/ip_k66f.dts:118 */
				pinctrl-0 = < &enet_default >; /* in zephyr/boards/segger/ip_k66f/ip_k66f.dts:119 */
				pinctrl-names = "default";     /* in zephyr/boards/segger/ip_k66f/ip_k66f.dts:120 */
				phandle = < 0xe >;             /* in zephyr/dts/arm/nxp/nxp_k6x.dtsi:485 */

				/* node '/soc/ethernet@400c0000/mdio/phy@0' defined in zephyr/boards/segger/ip_k66f/ip_k66f.dts:122 */
				phy: phy@0 {
					compatible = "ethernet-phy";          /* in zephyr/boards/segger/ip_k66f/ip_k66f.dts:123 */
					reg = < 0x0 >;                        /* in zephyr/boards/segger/ip_k66f/ip_k66f.dts:124 */
					status = "okay";                      /* in zephyr/boards/segger/ip_k66f/ip_k66f.dts:125 */
					fixed-link = "100BASE-T Full-Duplex"; /* in zephyr/boards/segger/ip_k66f/ip_k66f.dts:126 */
					phandle = < 0x11 >;                   /* in zephyr/boards/segger/ip_k66f/ip_k66f.dts:114 */
				};
			};

			/* node '/soc/ethernet@400c0000/ptp_clock' defined in zephyr/dts/arm/nxp/nxp_k6x.dtsi:498 */
			enet_ptp_clock: ptp_clock {
				compatible = "nxp,enet-ptp-clock"; /* in zephyr/dts/arm/nxp/nxp_k6x.dtsi:499 */
				interrupts = < 0x52 0x0 >;         /* in zephyr/dts/arm/nxp/nxp_k6x.dtsi:500 */
				interrupt-names = "IEEE1588_TMR";  /* in zephyr/dts/arm/nxp/nxp_k6x.dtsi:501 */
				clocks = < &sim 0x10e2 0x0 0x0 >;  /* in zephyr/dts/arm/nxp/nxp_k6x.dtsi:502 */
				status = "disabled";               /* in zephyr/dts/arm/nxp/nxp_k6x.dtsi:503 */
				phandle = < 0xf >;                 /* in zephyr/dts/arm/nxp/nxp_k6x.dtsi:486 */
			};
		};

		/* node '/soc/random@40029000' defined in zephyr/dts/arm/nxp/nxp_k6x.dtsi:507 */
		rnga: random@40029000 {
			compatible = "nxp,kinetis-rnga"; /* in zephyr/dts/arm/nxp/nxp_k6x.dtsi:508 */
			reg = < 0x40029000 0x1000 >;     /* in zephyr/dts/arm/nxp/nxp_k6x.dtsi:509 */
			status = "okay";                 /* in zephyr/dts/arm/nxp/nxp_k6x.dtsi:510 */
			interrupts = < 0x17 0x0 >;       /* in zephyr/dts/arm/nxp/nxp_k6x.dtsi:511 */
		};

		/* node '/soc/can@40024000' defined in zephyr/dts/arm/nxp/nxp_k6x.dtsi:514 */
		flexcan0: can@40024000 {
			compatible = "nxp,flexcan";       /* in zephyr/dts/arm/nxp/nxp_k6x.dtsi:515 */
			reg = < 0x40024000 0x1000 >;      /* in zephyr/dts/arm/nxp/nxp_k6x.dtsi:516 */
			interrupts = < 0x4b 0x0 >,
			             < 0x4c 0x0 >,
			             < 0x4d 0x0 >,
			             < 0x4e 0x0 >,
			             < 0x4f 0x0 >,
			             < 0x50 0x0 >;        /* in zephyr/dts/arm/nxp/nxp_k6x.dtsi:517 */
			interrupt-names = "mb-0-15",
			                  "bus-off",
			                  "error",
			                  "tx-warning",
			                  "rx-warning",
			                  "wake-up";      /* in zephyr/dts/arm/nxp/nxp_k6x.dtsi:518 */
			clocks = < &sim 0x2 0x103c 0x4 >; /* in zephyr/dts/arm/nxp/nxp_k6x.dtsi:519 */
			clk-source = < 0x1 >;             /* in zephyr/dts/arm/nxp/nxp_k6x.dtsi:520 */
			status = "disabled";              /* in zephyr/dts/arm/nxp/nxp_k6x.dtsi:521 */
		};

		/* node '/soc/dma-controller@40008000' defined in zephyr/dts/arm/nxp/nxp_k6x.dtsi:524 */
		edma0: dma-controller@40008000 {
			#dma-cells = < 0x2 >;             /* in zephyr/dts/arm/nxp/nxp_k6x.dtsi:525 */
			compatible = "nxp,mcux-edma";     /* in zephyr/dts/arm/nxp/nxp_k6x.dtsi:526 */
			nxp,version = < 0x2 >;            /* in zephyr/dts/arm/nxp/nxp_k6x.dtsi:527 */
			dma-channels = < 0x10 >;          /* in zephyr/dts/arm/nxp/nxp_k6x.dtsi:528 */
			dma-requests = < 0x40 >;          /* in zephyr/dts/arm/nxp/nxp_k6x.dtsi:529 */
			nxp,mem2mem;                      /* in zephyr/dts/arm/nxp/nxp_k6x.dtsi:530 */
			reg = < 0x40008000 0x1000 >,
			      < 0x40021000 0x1000 >;      /* in zephyr/dts/arm/nxp/nxp_k6x.dtsi:531 */
			interrupts = < 0x0 0x0 >,
			             < 0x1 0x0 >,
			             < 0x2 0x0 >,
			             < 0x3 0x0 >,
			             < 0x4 0x0 >,
			             < 0x5 0x0 >,
			             < 0x6 0x0 >,
			             < 0x7 0x0 >,
			             < 0x8 0x0 >,
			             < 0x9 0x0 >,
			             < 0xa 0x0 >,
			             < 0xb 0x0 >,
			             < 0xc 0x0 >,
			             < 0xd 0x0 >,
			             < 0xe 0x0 >,
			             < 0xf 0x0 >,
			             < 0x10 0x0 >;        /* in zephyr/dts/arm/nxp/nxp_k6x.dtsi:533 */
			clocks = < &sim 0x0 0x1040 0x2 >,
			         < &sim 0x2 0x103c 0x2 >; /* in zephyr/dts/arm/nxp/nxp_k6x.dtsi:538 */
			status = "disabled";              /* in zephyr/dts/arm/nxp/nxp_k6x.dtsi:540 */
			phandle = < 0x9 >;                /* in zephyr/dts/arm/nxp/nxp_k6x.dtsi:340 */
		};

		/* node '/soc/pit@40037000' defined in zephyr/dts/arm/nxp/nxp_k6x.dtsi:543 */
		pit0: pit@40037000 {
			compatible = "nxp,pit";            /* in zephyr/dts/arm/nxp/nxp_k6x.dtsi:544 */
			reg = < 0x40037000 0x1000 >;       /* in zephyr/dts/arm/nxp/nxp_k6x.dtsi:545 */
			clocks = < &sim 0x2 0x103c 0x17 >; /* in zephyr/dts/arm/nxp/nxp_k6x.dtsi:546 */
			status = "disabled";               /* in zephyr/dts/arm/nxp/nxp_k6x.dtsi:547 */
			max-load-value = < 0xffffffff >;   /* in zephyr/dts/arm/nxp/nxp_k6x.dtsi:548 */
			#address-cells = < 0x1 >;          /* in zephyr/dts/arm/nxp/nxp_k6x.dtsi:549 */
			#size-cells = < 0x0 >;             /* in zephyr/dts/arm/nxp/nxp_k6x.dtsi:550 */

			/* node '/soc/pit@40037000/pit0_channel@0' defined in zephyr/dts/arm/nxp/nxp_k6x.dtsi:552 */
			pit0_channel0: pit0_channel@0 {
				compatible = "nxp,pit-channel"; /* in zephyr/dts/arm/nxp/nxp_k6x.dtsi:553 */
				reg = < 0x0 >;                  /* in zephyr/dts/arm/nxp/nxp_k6x.dtsi:554 */
				interrupts = < 0x30 0x0 >;      /* in zephyr/dts/arm/nxp/nxp_k6x.dtsi:555 */
				status = "disabled";            /* in zephyr/dts/arm/nxp/nxp_k6x.dtsi:556 */
			};

			/* node '/soc/pit@40037000/pit0_channel@1' defined in zephyr/dts/arm/nxp/nxp_k6x.dtsi:559 */
			pit0_channel1: pit0_channel@1 {
				compatible = "nxp,pit-channel"; /* in zephyr/dts/arm/nxp/nxp_k6x.dtsi:560 */
				reg = < 0x1 >;                  /* in zephyr/dts/arm/nxp/nxp_k6x.dtsi:561 */
				interrupts = < 0x31 0x0 >;      /* in zephyr/dts/arm/nxp/nxp_k6x.dtsi:562 */
				status = "disabled";            /* in zephyr/dts/arm/nxp/nxp_k6x.dtsi:563 */
			};

			/* node '/soc/pit@40037000/pit0_channel@2' defined in zephyr/dts/arm/nxp/nxp_k6x.dtsi:566 */
			pit0_channel2: pit0_channel@2 {
				compatible = "nxp,pit-channel"; /* in zephyr/dts/arm/nxp/nxp_k6x.dtsi:567 */
				reg = < 0x2 >;                  /* in zephyr/dts/arm/nxp/nxp_k6x.dtsi:568 */
				interrupts = < 0x32 0x0 >;      /* in zephyr/dts/arm/nxp/nxp_k6x.dtsi:569 */
				status = "disabled";            /* in zephyr/dts/arm/nxp/nxp_k6x.dtsi:570 */
			};

			/* node '/soc/pit@40037000/pit0_channel@3' defined in zephyr/dts/arm/nxp/nxp_k6x.dtsi:573 */
			pit0_channel3: pit0_channel@3 {
				compatible = "nxp,pit-channel"; /* in zephyr/dts/arm/nxp/nxp_k6x.dtsi:574 */
				reg = < 0x3 >;                  /* in zephyr/dts/arm/nxp/nxp_k6x.dtsi:575 */
				interrupts = < 0x33 0x0 >;      /* in zephyr/dts/arm/nxp/nxp_k6x.dtsi:576 */
				status = "disabled";            /* in zephyr/dts/arm/nxp/nxp_k6x.dtsi:577 */
			};
		};

		/* node '/soc/lpuart@400c4000' defined in zephyr/dts/arm/nxp/nxp_k66.dtsi:17 */
		lpuart0: lpuart@400c4000 {
			compatible = "nxp,lpuart";         /* in zephyr/dts/arm/nxp/nxp_k66.dtsi:18 */
			reg = < 0x400c4000 0x14 >;         /* in zephyr/dts/arm/nxp/nxp_k66.dtsi:19 */
			interrupts = < 0x56 0x0 >;         /* in zephyr/dts/arm/nxp/nxp_k66.dtsi:20 */
			clocks = < &sim 0x0 0x1038 0x14 >; /* in zephyr/dts/arm/nxp/nxp_k66.dtsi:21 */
			dmas = < &edma0 0x1 0x3a >,
			       < &edma0 0x2 0x3b >;        /* in zephyr/dts/arm/nxp/nxp_k66.dtsi:22 */
			dma-names = "rx",
			            "tx";                  /* in zephyr/dts/arm/nxp/nxp_k66.dtsi:23 */
			status = "disabled";               /* in zephyr/dts/arm/nxp/nxp_k66.dtsi:24 */
		};

		/* node '/soc/can@400a4000' defined in zephyr/dts/arm/nxp/nxp_k66.dtsi:27 */
		flexcan1: can@400a4000 {
			compatible = "nxp,flexcan";       /* in zephyr/dts/arm/nxp/nxp_k66.dtsi:28 */
			reg = < 0x400a4000 0x1000 >;      /* in zephyr/dts/arm/nxp/nxp_k66.dtsi:29 */
			interrupts = < 0x5e 0x0 >,
			             < 0x5f 0x0 >,
			             < 0x60 0x0 >,
			             < 0x61 0x0 >,
			             < 0x62 0x0 >,
			             < 0x63 0x0 >;        /* in zephyr/dts/arm/nxp/nxp_k66.dtsi:30 */
			interrupt-names = "mb-0-15",
			                  "bus-off",
			                  "error",
			                  "tx-warning",
			                  "rx-warning",
			                  "wake-up";      /* in zephyr/dts/arm/nxp/nxp_k66.dtsi:31 */
			clocks = < &sim 0x2 0x1030 0x4 >; /* in zephyr/dts/arm/nxp/nxp_k66.dtsi:33 */
			clk-source = < 0x1 >;             /* in zephyr/dts/arm/nxp/nxp_k66.dtsi:34 */
			status = "disabled";              /* in zephyr/dts/arm/nxp/nxp_k66.dtsi:35 */
		};
	};

	/* node '/cpus' defined in zephyr/dts/arm/nxp/nxp_k6x.dtsi:22 */
	cpus {
		#address-cells = < 0x1 >; /* in zephyr/dts/arm/nxp/nxp_k6x.dtsi:23 */
		#size-cells = < 0x0 >;    /* in zephyr/dts/arm/nxp/nxp_k6x.dtsi:24 */

		/* node '/cpus/cpu@0' defined in zephyr/dts/arm/nxp/nxp_k6x.dtsi:26 */
		cpu0: cpu@0 {
			device_type = "cpu";             /* in zephyr/dts/arm/nxp/nxp_k6x.dtsi:27 */
			compatible = "arm,cortex-m4f";   /* in zephyr/dts/arm/nxp/nxp_k6x.dtsi:28 */
			reg = < 0x0 >;                   /* in zephyr/dts/arm/nxp/nxp_k6x.dtsi:29 */
			clock-frequency = < 0x7270e00 >; /* in zephyr/boards/segger/ip_k66f/ip_k66f.dts:45 */
		};
	};

	/* node '/memory@1fff0000' defined in zephyr/dts/arm/nxp/nxp_k6x.dtsi:42 */
	sram_l: memory@1fff0000 {
		compatible = "zephyr,memory-region",
		             "mmio-sram";            /* in zephyr/dts/arm/nxp/nxp_k6x.dtsi:43 */
		reg = < 0x1fff0000 0x10000 >;        /* in zephyr/dts/arm/nxp/nxp_k6x.dtsi:44 */
		zephyr,memory-region = "SRAML";      /* in zephyr/dts/arm/nxp/nxp_k6x.dtsi:45 */
	};

	/* node '/memory@20000000' defined in zephyr/dts/arm/nxp/nxp_k6x.dtsi:48 */
	sram0: memory@20000000 {
		compatible = "mmio-sram";     /* in zephyr/dts/arm/nxp/nxp_k6x.dtsi:49 */
		reg = < 0x20000000 0x30000 >; /* in zephyr/dts/arm/nxp/nxp_k6x.dtsi:50 */
	};

	/* node '/temp0' defined in zephyr/dts/arm/nxp/nxp_k6x.dtsi:53 */
	temp0: temp0 {
		compatible = "nxp,kinetis-temperature"; /* in zephyr/dts/arm/nxp/nxp_k6x.dtsi:54 */
		io-channels = < &adc0 0x1a >,
		              < &adc0 0x1b >;           /* in zephyr/dts/arm/nxp/nxp_k6x.dtsi:55 */
		io-channel-names = "SENSOR",
		                   "BANDGAP";           /* in zephyr/dts/arm/nxp/nxp_k6x.dtsi:56 */
		bandgap-voltage = < 0xf4240 >;          /* in zephyr/dts/arm/nxp/nxp_k6x.dtsi:57 */
		vtemp25 = < 0xaece0 >;                  /* in zephyr/dts/arm/nxp/nxp_k6x.dtsi:58 */
		sensor-slope-cold = < 0x654 >;          /* in zephyr/dts/arm/nxp/nxp_k6x.dtsi:59 */
		sensor-slope-hot = < 0x654 >;           /* in zephyr/dts/arm/nxp/nxp_k6x.dtsi:60 */
		status = "disabled";                    /* in zephyr/dts/arm/nxp/nxp_k6x.dtsi:61 */
	};

	/* node '/temp1' defined in zephyr/dts/arm/nxp/nxp_k6x.dtsi:64 */
	temp1: temp1 {
		compatible = "nxp,kinetis-temperature"; /* in zephyr/dts/arm/nxp/nxp_k6x.dtsi:65 */
		io-channels = < &adc1 0x1a >,
		              < &adc1 0x1b >;           /* in zephyr/dts/arm/nxp/nxp_k6x.dtsi:66 */
		io-channel-names = "SENSOR",
		                   "BANDGAP";           /* in zephyr/dts/arm/nxp/nxp_k6x.dtsi:67 */
		bandgap-voltage = < 0xf4240 >;          /* in zephyr/dts/arm/nxp/nxp_k6x.dtsi:68 */
		vtemp25 = < 0xaece0 >;                  /* in zephyr/dts/arm/nxp/nxp_k6x.dtsi:69 */
		sensor-slope-cold = < 0x654 >;          /* in zephyr/dts/arm/nxp/nxp_k6x.dtsi:70 */
		sensor-slope-hot = < 0x654 >;           /* in zephyr/dts/arm/nxp/nxp_k6x.dtsi:71 */
		status = "disabled";                    /* in zephyr/dts/arm/nxp/nxp_k6x.dtsi:72 */
	};

	/* node '/pinctrl' defined in zephyr/dts/arm/nxp/nxp_k6x.dtsi:76 */
	pinctrl: pinctrl {
		compatible = "nxp,port-pinctrl"; /* in zephyr/dts/arm/nxp/nxp_k6x.dtsi:77 */
		status = "okay";                 /* in zephyr/dts/arm/nxp/nxp_k6x.dtsi:78 */

		/* node '/pinctrl/enet_default' defined in zephyr/boards/segger/ip_k66f/ip_k66f-pinctrl.dtsi:12 */
		enet_default: enet_default {
			phandle = < 0x10 >; /* in zephyr/boards/segger/ip_k66f/ip_k66f.dts:110 */

			/* node '/pinctrl/enet_default/group0' defined in zephyr/boards/segger/ip_k66f/ip_k66f-pinctrl.dtsi:13 */
			group0 {
				pinmux = < 0x3000400 >,
				         < 0x3400400 >,
				         < 0x3800400 >,
				         < 0x3c00400 >,
				         < 0x4000400 >,
				         < 0x4400400 >,
				         < 0x46800200 >; /* in zephyr/boards/segger/ip_k66f/ip_k66f-pinctrl.dtsi:14 */
				drive-strength = "low";  /* in zephyr/boards/segger/ip_k66f/ip_k66f-pinctrl.dtsi:21 */
				slew-rate = "fast";      /* in zephyr/boards/segger/ip_k66f/ip_k66f-pinctrl.dtsi:22 */
			};
		};

		/* node '/pinctrl/spi1_default' defined in zephyr/boards/segger/ip_k66f/ip_k66f-pinctrl.dtsi:26 */
		spi1_default: spi1_default {
			phandle = < 0xa >; /* in zephyr/boards/segger/ip_k66f/ip_k66f.dts:132 */

			/* node '/pinctrl/spi1_default/group0' defined in zephyr/boards/segger/ip_k66f/ip_k66f-pinctrl.dtsi:27 */
			group0 {
				pinmux = < 0x12800200 >,
				         < 0x12c00200 >,
				         < 0x14000200 >,
				         < 0x14400200 >; /* in zephyr/boards/segger/ip_k66f/ip_k66f-pinctrl.dtsi:28 */
				drive-strength = "low";  /* in zephyr/boards/segger/ip_k66f/ip_k66f-pinctrl.dtsi:32 */
				slew-rate = "fast";      /* in zephyr/boards/segger/ip_k66f/ip_k66f-pinctrl.dtsi:33 */
			};
		};
	};

	/* node '/leds' defined in zephyr/boards/segger/ip_k66f/ip_k66f.dts:29 */
	leds {
		compatible = "gpio-leds"; /* in zephyr/boards/segger/ip_k66f/ip_k66f.dts:30 */

		/* node '/leds/led_0' defined in zephyr/boards/segger/ip_k66f/ip_k66f.dts:32 */
		red0_led: led_0 {
			gpios = < &gpioa 0x8 0x0 >; /* in zephyr/boards/segger/ip_k66f/ip_k66f.dts:33 */
			label = "User LD1";         /* in zephyr/boards/segger/ip_k66f/ip_k66f.dts:34 */
		};

		/* node '/leds/led_2' defined in zephyr/boards/segger/ip_k66f/ip_k66f.dts:37 */
		red2_led: led_2 {
			gpios = < &gpioa 0xa 0x0 >; /* in zephyr/boards/segger/ip_k66f/ip_k66f.dts:38 */
			label = "User LD2";         /* in zephyr/boards/segger/ip_k66f/ip_k66f.dts:39 */
		};
	};
};
